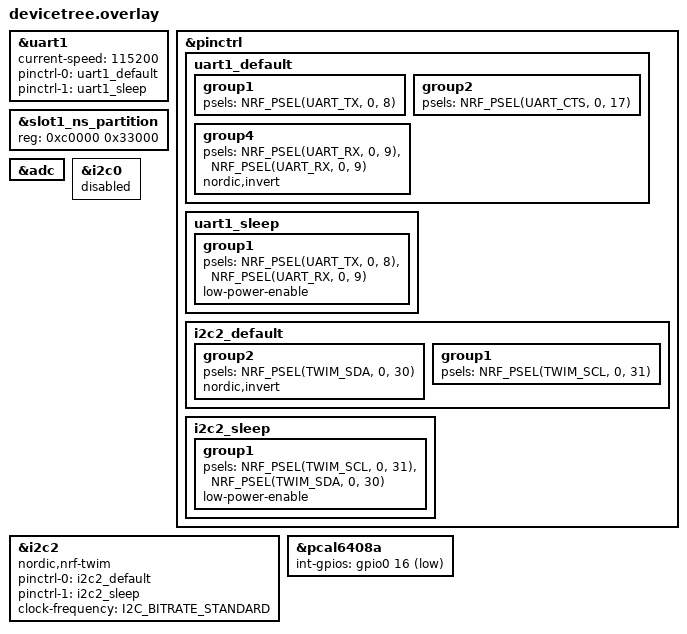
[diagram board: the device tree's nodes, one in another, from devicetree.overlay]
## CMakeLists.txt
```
cmake_minimum_required(VERSION 3.20.0)
find_package(Zephyr REQUIRED HINTS $ENV{ZEPHYR_BASE})
project(mbc_nrf9151_core_v1)

target_sources(app PRIVATE
  src/main.c
  src/biosignal.c
  src/ecg.c  
  src/i2c_helper.c
  src/spo2.c
  src/max30102.c
  src/robot.c
)
```

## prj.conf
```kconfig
# UART y consola
CONFIG_UART_INTERRUPT_DRIVEN=y
CONFIG_SERIAL=y
CONFIG_CONSOLE=y
CONFIG_UART_CONSOLE=y
CONFIG_STDOUT_CONSOLE=y

# GPIO y LED
CONFIG_GPIO=y

# Hilos y pila principal
CONFIG_MAIN_STACK_SIZE=1024
CONFIG_THREAD_NAME=y

# Logs y consola
CONFIG_PRINTK=y

# Librería C
CONFIG_NEWLIB_LIBC=y
CONFIG_NEWLIB_LIBC_FLOAT_PRINTF=y

# ADC
CONFIG_ADC=y
CONFIG_NRFX_SAADC=y

# Pin control
CONFIG_PINCTRL=y

# I2C
CONFIG_I2C=y
CONFIG_I2C_NRFX=y

CONFIG_HEAP_MEM_POOL_SIZE=8192
```

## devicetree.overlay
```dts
&uart1 {
    status = "okay";
    current-speed = <115200>;
    pinctrl-0 = <&uart1_default>;
    pinctrl-1 = <&uart1_sleep>;
    pinctrl-names = "default", "sleep";
};

&pinctrl {
    uart1_default: uart1_default {
        group1 {
            psels = <NRF_PSEL(UART_TX, 0, 8)>;
        };

        group2 {
            psels = <NRF_PSEL(UART_CTS, 0, 17)>;
        };

        group4 {
            psels = <NRF_PSEL(UART_RX, 0, 9)>, <NRF_PSEL(UART_RX, 0, 9)>;
            nordic,invert;
        };
    };

    uart1_sleep: uart1_sleep {
        group1 {
            psels = <NRF_PSEL(UART_TX, 0, 8)>,
                    <NRF_PSEL(UART_RX, 0, 9)>;
            low-power-enable;
        };
    };

};


&slot1_ns_partition {
    reg = <0xc0000 0x33000>;
};

&adc {
    status = "okay";
};

&i2c0 {
    status = "disabled";
};


&i2c2 {
    status = "okay";
    compatible = "nordic,nrf-twim";
    pinctrl-0 = <&i2c2_default>;
    pinctrl-1 = <&i2c2_sleep>;
    pinctrl-names = "default", "sleep";
    clock-frequency = <I2C_BITRATE_STANDARD>; // 100kHz
};

&pinctrl {
    i2c2_default: i2c2_default {

        group2 {
            psels = <NRF_PSEL(TWIM_SDA, 0, 30)>;
            nordic,invert;
        };

        group1 {
            psels = <NRF_PSEL(TWIM_SCL, 0, 31)>;
        };
    };

    i2c2_sleep: i2c2_sleep {
        group1 {
            psels = <NRF_PSEL(TWIM_SCL, 0, 31)>, <NRF_PSEL(TWIM_SDA, 0, 30)>;
            low-power-enable;
        };
    };
};
&pcal6408a {
    status = "okay";
    int-gpios = <&gpio0 16 (GPIO_ACTIVE_LOW | GPIO_PULL_UP)>;
};
```

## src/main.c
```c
#include <zephyr/kernel.h>
#include <zephyr/device.h>
#include <zephyr/devicetree.h>
#include <zephyr/drivers/uart.h>
#include <zephyr/sys/printk.h>
#include <stdio.h>
#include <string.h>

// My includes
#include "biosignal.h"
#include "ecg.h"
//#include "fcg.h"
#include "i2c_helper.h"
#include "robot.h"  
#include "max30102.h"

// UART
#define UART_NODE DT_NODELABEL(uart1)
const struct device *uart_dev;

// Semaphore to trigger each task
struct k_sem ecg_sem;
//struct k_sem fcg_sem;
struct k_sem max30102_sem;
struct k_sem i2c_sem;

// Thread stacks and structures
K_THREAD_STACK_DEFINE(ecg_stack, 1024);
//K_THREAD_STACK_DEFINE(fcg_stack, 1024);
K_THREAD_STACK_DEFINE(uart_stack, 1024);
K_THREAD_STACK_DEFINE(max30102_stack, 1024);
K_THREAD_STACK_DEFINE(i2c_stack, 1024);

struct k_thread ecg_thread_data;
//struct k_thread fcg_thread_data;
struct k_thread uart_thread_data;
struct k_thread i2c_thread_data;
struct k_thread max30102_thread_data;

k_tid_t ecg_tid;
//k_tid_t fcg_tid;
k_tid_t uart_tid;
k_tid_t i2c_tid;    
k_tid_t max30102_tid;    

robot_t robot;


void i2c_thread(void *arg1, void *arg2, void *arg3) {
    const struct device *i2c_dev = i2c_helper_init();

    if (i2c_dev == NULL) {
        printk("[I2C] Initialization failed.\n");
        return;
    }

    printk("Starting I2C bus scan...\n");

    for (uint8_t addr = 0x03; addr <= 0x77; addr++) {
        struct i2c_msg msg;
        uint8_t dummy_tx = 0x00;

        msg.buf = &dummy_tx;
        msg.len = 1;
        msg.flags = I2C_MSG_WRITE | I2C_MSG_STOP;

        int ret = i2c_transfer(i2c_dev, &msg, 1, addr);

        if (ret == 0) {
            printk("Found device at 0x%02X\n", addr);
        }
        k_msleep(10); // pequeña espera para no saturar el bus
    }

    printk("I2C scan complete.\n");


    while (1) {
        // Wait for the semaphore to be given
        // Uncomment the next line to block the thread until the semaphore is given
        //k_sem_take(&i2c_sem, K_FOREVER);


        //printk("[I2C] Thread.\n");

    }
}


// ecg data capture simulation
void ecg_thread(void *arg1, void *arg2, void *arg3) {
    printk("[ECG] ecg thread started and waiting for signal...\n");

    while (1) {
        k_sem_take(&ecg_sem, K_FOREVER);
        printk("[ECG] Capturing data...\n");

        float *captured_ecg = ecg_sample_task();
        if (captured_ecg == NULL) {
            printk("[ECG] Error capturing data.\n");
            continue;
        } else {
            //biosignal_send_data_generic("ecg", captured_ecg, ecg_SAMPLES, 10.5, 78);
            biosignal_send_data("ECG", captured_ecg, ECG_SAMPLES);

        }

        printk("[ECG] Capture complete. Returning to wait state.\n");
    }
}

// FCG data capture simulation
/*void fcg_thread(void *arg1, void *arg2, void *arg3) {
    printk("[FCG] FCG thread started and waiting for signal...\n");

    while (1) {
        k_sem_take(&fcg_sem, K_FOREVER);
        printk("[FCG] Capturing data...\n");

        float *captured_fcg = fcg_sample_task();
        if (captured_fcg == NULL) {
            printk("[FCG] Error capturing data.\n");
            continue;
        } else {
            //biosignal_send_data_generic("fcg", captured_fcg, fcg_SAMPLES, 10.5, 78);
            biosignal_send_data("FCG", captured_fcg, FCG_SAMPLES);

        }

        printk("[FCG] Capture complete. Returning to wait state.\n");
    }
}*/


void max30102_thread(void *arg1, void *arg2, void *arg3) {
    const struct device *i2c_dev = i2c_helper_init();

    if (i2c_dev == NULL) {
        printk("[MAX30102] Initialization failed.\n");
        return;
    }

    initMax30102(i2c_dev);
    printk("[MAX30102] PPG thread started and waiting for signal...\n");

    while (1) {
        k_sem_take(&max30102_sem, K_FOREVER);
        printk("[MAX30102] Capturing data...\n");

        float *red_data = get30sRedLed();
        if (red_data == NULL) {
            printk("[MAX30102] Error capturing data.\n");
            continue;
        } else {
    
            //biosignal_send_data_generic("PPG", red_data, MAX30102_BUFFER_SIZE, 10.5, 78);
            biosignal_send_data("PPG", red_data, MAX30102_BUFFER_SIZE);
        }

        printk("[MAX30102] Capture complete. Returning to wait state.\n");
    }
}

void uart_thread(void *arg1, void *arg2, void *arg3) {
    unsigned char ch;
    char cmd_buf[64];
    int cmd_index = 0;

    printk("[UART] UART thread started. Waiting for commands...\n");

    while (1) {
        if (uart_poll_in(uart_dev, &ch) == 0) {
            uart_poll_out(uart_dev, ch);  // echo

            if (ch == '\r' || ch == '\n') {
                cmd_buf[cmd_index] = '\0';
                printk("\n[UART] Command received: %s\n", cmd_buf);

                if (strstr(cmd_buf, "<CMD>:START:ECG;")) {
                    printk("[UART] Trigger ECG capture.\n");
                    k_sem_give(&ecg_sem);
                } else if (strstr(cmd_buf, "<CMD>:START:PPG;")) {
                    printk("[UART] Trigger PPG capture.\n");
                    k_sem_give(&max30102_sem);
                }else if (strstr(cmd_buf, "<CMD>:START:FCG;")) {
                    printk("[UART] Trigger FCG capture.\n");
                    k_sem_give(&ecg_sem);
                }

                cmd_index = 0;
                memset(cmd_buf, 0, sizeof(cmd_buf));
            } else {
                if (cmd_index < sizeof(cmd_buf) - 1) {
                    cmd_buf[cmd_index++] = ch;
                }
            }
        } else {
            k_msleep(1);
        }
    }
}

int main(void) {
    uart_dev = DEVICE_DT_GET(UART_NODE);
    if (!device_is_ready(uart_dev)) {
        printk("[ERROR] UART not ready\n");
        return -1;
    }

    printk("[SYSTEM] UART initialized\n");

    biosignal_init(uart_dev);
    ecg_adc_init();
    fcg_adc_init();

    k_sem_init(&ecg_sem, 0, 1);
    //k_sem_init(&fcg_sem, 0, 1);
    k_sem_init(&max30102_sem, 0, 1);

    ecg_tid = k_thread_create(&ecg_thread_data, ecg_stack,
                              K_THREAD_STACK_SIZEOF(ecg_stack),
                              ecg_thread,
                              NULL, NULL, NULL,
                              4, 0, K_NO_WAIT);
    k_thread_name_set(ecg_tid, "ECG Thread");

    /*fcg_tid = k_thread_create(&fcg_thread_data, fcg_stack,
                              K_THREAD_STACK_SIZEOF(fcg_stack),
                              fcg_thread,
                              NULL, NULL, NULL,
                              4, 0, K_NO_WAIT);
    k_thread_name_set(fcg_tid, "FCG Thread");*/

    uart_tid = k_thread_create(&uart_thread_data, uart_stack,
                               K_THREAD_STACK_SIZEOF(uart_stack),
                               uart_thread,
                               NULL, NULL, NULL,
                               5, 0, K_NO_WAIT);
    k_thread_name_set(uart_tid, "UART Thread");

    max30102_tid = k_thread_create(&max30102_thread_data, max30102_stack,
                                   K_THREAD_STACK_SIZEOF(max30102_stack),
                                   max30102_thread,
                                   NULL, NULL, NULL,
                                   3, 0, K_NO_WAIT);
    k_thread_name_set(max30102_tid, "PPG Thread");

    /*i2c_tid = k_thread_create(&i2c_thread_data, i2c_stack,
        K_THREAD_STACK_SIZEOF(i2c_stack),
        i2c_thread,
        NULL, NULL, NULL,
        3, 0, K_NO_WAIT);
    k_thread_name_set(i2c_tid, "I2C Thread");*/


    return 0;
}
```

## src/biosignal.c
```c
#include "biosignal.h"
#include <stdio.h>
#include <string.h>
#include <math.h>

float fake_ecg_data[ECG_LEN];
float temp = 36.7f;
int hr = 78;

static char rx_buffer[256];
static int rx_index = 0;

static const struct device *uart_dev = NULL;

char buf[1024];
int offset = 0;


void biosignal_handle_rx(char c) {
    if (c == '\n' || c == '\r') {
        rx_buffer[rx_index] = '\0';  // finalizar cadena

        if (strncmp(rx_buffer, "<CMD>:", 6) == 0) {
            char *cmd_ptr = strstr(rx_buffer, "ACTION=");
            if (cmd_ptr) {
                cmd_ptr += 7;  // avanzar a valor de acción
                char ack_buf[64];
                snprintf(ack_buf, sizeof(ack_buf), "<RESP>:ACK=%s;\n", cmd_ptr);
                biosignal_send_uart(ack_buf);
            }
        }

        rx_index = 0;  // reiniciar índice
    } else {
        if (rx_index < sizeof(rx_buffer) - 1) {
            rx_buffer[rx_index++] = c;
        } else {
            rx_index = 0;  // overflow: reinicia
        }
    }
}

void biosignal_init(const struct device *uart) {
    uart_dev = uart;
}


void biosignal_generate_fake_ecg(void) {
    for (int i = 0; i < ECG_LEN; i++) {
        fake_ecg_data[i] = 0.5f + 0.2f * sinf((float)i / 5.0f);  // señal simulada
    }
}

void biosignal_send_uart(const char *data) {
    for (size_t i = 0; i < strlen(data); i++) {
        uart_poll_out(uart_dev, data[i]);
    }
}

void biosignal_send_data(const char *signal_type, float *ecg_array, int len) {
    offset = 0;
    memset(buf, 0, sizeof(buf));  // Limpia el contenido previo del buffer

    printk("Sending %s data.\n", signal_type);
    offset += snprintf(buf + offset, sizeof(buf) - offset, "<DATA>:%s=[", signal_type);    

    for (int i = 0; i < len; i++) {
        offset += snprintf(buf + offset, sizeof(buf) - offset,
                           "%.4f%s", (double)ecg_array[i], (i < len - 1) ? "," : "");
        
        if (offset >= sizeof(buf) - 20) {  // Evita overflow
            break;
        }
    }

    offset += snprintf(buf + offset, sizeof(buf) - offset,
                       "];TEMP=%.1f;HR=%d;\n", (double)temp, hr);

    printk("Sending %s data.\n", signal_type);
    biosignal_send_uart(buf);

    k_msleep(10); 
    uart_poll_out(uart_dev, '\r');
    uart_poll_out(uart_dev, '\n');
    k_msleep(10);  // Permite que el hardware termine de enviar
}


void biosignal_send_data_generic(const char *signal_type, float *data_array, int len, float temp_val, int hr_val) {
    char buf[1024];
    int offset = 0;

    printk("Sending %s data.\n", signal_type);
    
    offset += snprintf(buf + offset, sizeof(buf) - offset, "<DATA>:%s=[", signal_type);

    for (int i = 0; i < len; i++) {
        offset += snprintf(buf + offset, sizeof(buf) - offset,
                           "%.4f%s", (double)data_array[i], (i < len - 1) ? "," : "");
        
        if (offset >= sizeof(buf) - 20) {  // Prevent overflow
            break;
        }
    }

    offset += snprintf(buf + offset, sizeof(buf) - offset,
                       "];TEMP=%.1f;HR=%d;\n", (double)temp_val, hr_val);

    printk("Sending %s data.\n", signal_type);
    biosignal_send_uart(buf);
}
```

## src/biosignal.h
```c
#ifndef BIOSIGNAL_H
#define BIOSIGNAL_H

#include <zephyr/device.h>
#include <zephyr/devicetree.h>
#include <zephyr/drivers/uart.h>
#include <zephyr/kernel.h>
// Después (correcto)
#include <stddef.h>  // para size_t

#define ECG_LEN 128

extern float ecg_data[ECG_LEN];
extern float temp;
extern int hr;

void biosignal_init(const struct device *uart);
void biosignal_generate_fake_ecg(void);
void biosignal_handle_rx(char c);
void biosignal_send_data(const char *signal_type, float *ecg_array, int len);
void biosignal_send_uart(const char *data);
void biosignal_send_data_generic(const char *signal_type, float *data_array, int len, float temp_val, int hr_val);

#endif // BIOSIGNAL_H
```

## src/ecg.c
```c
// ecg_adc.c
#include <nrfx_saadc.h>

#include "ecg.h"
#include <zephyr/kernel.h>
#include <zephyr/sys/printk.h>
#include <zephyr/drivers/adc.h>
#include <string.h>


const struct device *ecg_adc_dev = NULL;
uint16_t ecg_data[ECG_SAMPLES];
static struct adc_channel_cfg adc_cfg;
static struct adc_sequence sequence;
static uint16_t sample_buffer[ECG_SAMPLES];

int ecg_adc_init(void) {
    ecg_adc_dev = DEVICE_DT_GET(DT_NODELABEL(adc));
    if (!device_is_ready(ecg_adc_dev)) {
        printk("ADC device not ready\n");
        return -1;
    }

    adc_cfg.channel_id = ECG_ADC_CHANNEL;
    adc_cfg.gain = ECG_ADC_GAIN;
    adc_cfg.reference = ECG_ADC_REFERENCE;
    adc_cfg.acquisition_time = ECG_ADC_ACQUISITION_TIME;
    adc_cfg.input_positive = ECG_ADC_INPUT;

    int ret = adc_channel_setup(ecg_adc_dev, &adc_cfg);
    if (ret != 0) {
        printk("ADC channel setup failed (%d)\n", ret);
        return ret;
    }

    sequence.options = NULL;
    sequence.channels = BIT(ECG_ADC_CHANNEL);
    sequence.buffer = sample_buffer;
    sequence.buffer_size = sizeof(sample_buffer);
    sequence.resolution = ECG_ADC_RESOLUTION;

    return 0;
}


int fcg_adc_init(void) {
    ecg_adc_dev = DEVICE_DT_GET(DT_NODELABEL(adc));
    if (!device_is_ready(ecg_adc_dev)) {
        printk("ADC device not ready\n");
        return -1;
    }

    adc_cfg.channel_id = FCG_ADC_CHANNEL;
    adc_cfg.gain = ECG_ADC_GAIN;
    adc_cfg.reference = ECG_ADC_REFERENCE;
    adc_cfg.acquisition_time = ECG_ADC_ACQUISITION_TIME;
    adc_cfg.input_positive = FCG_ADC_INPUT;

    int ret = adc_channel_setup(ecg_adc_dev, &adc_cfg);
    if (ret != 0) {
        printk("ADC channel setup failed (%d)\n", ret);
        return ret;
    }

    sequence.options = NULL;
    sequence.channels = BIT(ECG_ADC_CHANNEL);
    sequence.buffer = sample_buffer;
    sequence.buffer_size = sizeof(sample_buffer);
    sequence.resolution = ECG_ADC_RESOLUTION;

    return 0;
}


/*void ecg_sample_task(void) {
    for (int i = 0; i < ECG_SAMPLES; i++) {
        int ret = adc_read(adc_dev, &sequence);
        if (ret != 0) {
            printk("ADC read failed: %d\n", ret);
            break;
        }
        ecg_data[i] = sample_buffer[0];
        k_sleep(K_MSEC(1));  // 1kHz sampling
    }
    printk("ECG sampling complete\n");
}*/

float* ecg_sample_task(void) {
    static float ecg_data[ECG_SAMPLES];

    for (int i = 0; i < ECG_SAMPLES; i++) {
        int ret = adc_read(ecg_adc_dev, &sequence);
        if (ret != 0) {
            printk("ADC read failed: %d\n", ret);
            return NULL;
        }
        // Convert ADC sample to millivolts
        float millivolts = ((float)sample_buffer[0]) * (SAADC_REF_VOLTAGE / SAADC_GAIN) * 1000.0f / ADC_RESOLUTION;
        //printk("Sample %d: %d mV\n", i, (float)millivolts);
        ecg_data[i] = millivolts;
        k_sleep(K_MSEC(1));  // 1kHz sampling rate
    }

    printk("ECG sampling complete\n");
    return ecg_data;
}

float* fcg_sample_task(void) {
    static float ecg_data[ECG_SAMPLES];

    for (int i = 0; i < ECG_SAMPLES; i++) {
        int ret = adc_read(ecg_adc_dev, &sequence);
        if (ret != 0) {
            printk("ADC read failed: %d\n", ret);
            return NULL;
        }
        // Convert ADC sample to millivolts
        float millivolts = ((float)sample_buffer[0]) * (SAADC_REF_VOLTAGE / SAADC_GAIN) * 1000.0f / ADC_RESOLUTION;
        //printk("Sample %d: %d mV\n", i, (float)millivolts);
        ecg_data[i] = millivolts;
        k_sleep(K_MSEC(1));  // 1kHz sampling rate
    }

    printk("FCG sampling complete\n");
    return ecg_data;
}
```

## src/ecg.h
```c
#ifndef ECG_ADC_H
#define ECG_ADC_H

#include <zephyr/device.h>
#include <zephyr/drivers/adc.h>
#include <zephyr/kernel.h>

#define ECG_SAMPLES         30000      // 30 segundos a 1kHz
#define ECG_ADC_RESOLUTION  12         // 12 bits
#define ECG_ADC_CHANNEL     0          // Canal AIN0
#define ECG_ADC_INPUT       NRF_SAADC_INPUT_AIN0
#define ECG_ADC_GAIN        ADC_GAIN_1_6
#define ECG_ADC_REFERENCE   ADC_REF_INTERNAL
#define ECG_ADC_ACQUISITION_TIME ADC_ACQ_TIME(ADC_ACQ_TIME_MICROSECONDS, 10)
#define ECG_ADC_NODE        DT_LABEL(DT_NODELABEL(adc))

#define FCG_ADC_CHANNEL     1          // Canal AIN1
#define FCG_ADC_INPUT       NRF_SAADC_INPUT_AIN1

#define SAADC_GAIN         (1.0f / 6.0f)
#define SAADC_REF_VOLTAGE  0.6f  // V
#define ADC_RESOLUTION     4096.0f  // 12 bits


extern int16_t ecg_buffer[ECG_SAMPLES];  // Buffer para los datos crudos
extern struct k_sem ecg_done;            // Semáforo para indicar fin de adquisición

int ecg_adc_init(void);
int fcg_adc_init(void);
//void ecg_sample_task(void);
float* ecg_sample_task(void);
float* fcg_sample_task(void);

    
#endif // ECG_ADC_H
```

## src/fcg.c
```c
// fcg_adc.c
#include <nrfx_saadc.h>

#include "fcg.h"
#include <zephyr/kernel.h>
#include <zephyr/sys/printk.h>
#include <zephyr/drivers/adc.h>
#include <string.h>


const struct device *fcg_adc_dev = NULL;
uint16_t fcg_data[FCG_SAMPLES];
static struct adc_channel_cfg adc_cfg;
static struct adc_sequence sequence;
static uint16_t sample_buffer[FCG_SAMPLES];

int fcg_adc_init(void) {
    fcg_adc_dev = DEVICE_DT_GET(DT_NODELABEL(adc));
    if (!device_is_ready(fcg_adc_dev)) {
        printk("ADC device not ready\n");
        return -1;
    }

    adc_cfg.channel_id = FCG_ADC_CHANNEL;
    adc_cfg.gain = FCG_ADC_GAIN;
    adc_cfg.reference = FCG_ADC_REFERENCE;
    adc_cfg.acquisition_time = FCG_ADC_ACQUISITION_TIME;
    adc_cfg.input_positive = FCG_ADC_INPUT;

    int ret = adc_channel_setup(fcg_adc_dev, &adc_cfg);
    if (ret != 0) {
        printk("ADC channel setup failed (%d)\n", ret);
        return ret;
    }

    sequence.options = NULL;
    sequence.channels = BIT(FCG_ADC_CHANNEL);
    sequence.buffer = sample_buffer;
    sequence.buffer_size = sizeof(sample_buffer);
    sequence.resolution = FCG_ADC_RESOLUTION;

    return 0;
}

/*void fcg_sample_task(void) {
    for (int i = 0; i < FCG_SAMPLES; i++) {
        int ret = adc_read(adc_dev, &sequence);
        if (ret != 0) {
            printk("ADC read failed: %d\n", ret);
            break;
        }
        fcg_data[i] = sample_buffer[0];
        k_sleep(K_MSEC(1));  // 1kHz sampling
    }
    printk("FCG sampling complete\n");
}*/

float* fcg_sample_task(void) {
    static float fcg_data[FCG_SAMPLES];

    for (int i = 0; i < FCG_SAMPLES; i++) {
        int ret = adc_read(fcg_adc_dev, &sequence);
        if (ret != 0) {
            printk("ADC read failed: %d\n", ret);
            return NULL;
        }
        // Convert ADC sample to millivolts
        float millivolts = ((float)sample_buffer[0]) * (SAADC_REF_VOLTAGE / SAADC_GAIN) * 1000.0f / ADC_RESOLUTION;
        //printk("Sample %d: %d mV\n", i, (float)millivolts);
        fcg_data[i] = millivolts;
        k_sleep(K_MSEC(1));  // 1kHz sampling rate
    }

    printk("FCG sampling complete\n");
    return fcg_data;
}
```

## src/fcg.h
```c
#ifndef FCG_ADC_H
#define FCG_ADC_H

#include <zephyr/device.h>
#include <zephyr/drivers/adc.h>
#include <zephyr/kernel.h>

#define FCG_SAMPLES         30000      // 30 segundos a 1kHz
#define FCG_ADC_RESOLUTION  12         // 12 bits
#define FCG_ADC_CHANNEL     0          // Canal AIN0
#define FCG_ADC_INPUT       NRF_SAADC_INPUT_AIN1
#define FCG_ADC_GAIN        ADC_GAIN_1_6
#define FCG_ADC_REFERENCE   ADC_REF_INTERNAL
#define FCG_ADC_ACQUISITION_TIME ADC_ACQ_TIME(ADC_ACQ_TIME_MICROSECONDS, 10)
#define FCG_ADC_NODE        DT_LABEL(DT_NODELABEL(adc))

#define SAADC_GAIN         (1.0f / 6.0f)
#define SAADC_REF_VOLTAGE  0.6f  // V
#define ADC_RESOLUTION     4096.0f  // 12 bits


extern int16_t fcg_buffer[FCG_SAMPLES];  // Buffer para los datos crudos
extern struct k_sem fcg_done;            // Semáforo para indicar fin de adquisición

int fcg_adc_init(void);
//void fcg_sample_task(void);
float* fcg_sample_task(void);

    
#endif // FCG_ADC_H
```

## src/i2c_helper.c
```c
#include "i2c_helper.h"
#include <zephyr/kernel.h>
#include <zephyr/sys/printk.h>
#include <math.h>
#include "max30102.h"
#include "spo2.h"



#define LED_BRIGHTNESS   0x1F
#define SAMPLE_AVG       2  // SAMPLEAVG_4
#define LED_MODE         3  // MODE_RED_IR
#define SAMPLE_RATE      3  // SAMPLERATE_400
#define PULSE_WIDTH      3  // PULSEWIDTH_411
#define ADC_RANGE        1  // ADCRANGE_4096
 
max30102_t sensor;

const struct device *i2c_helper_init(void) {
    const struct device *i2c_dev = DEVICE_DT_GET(I2C_HELPER_NODE);
    
    if (!device_is_ready(i2c_dev)) {
        printk("I2C: Device not ready.\n");
        return NULL;
    }

    return i2c_dev;
}

int i2c_helper_read_reg(const struct device *i2c_dev, uint8_t dev_addr, uint8_t reg_addr, uint8_t *value) {
    //return i2c_write_read(i2c_dev, dev_addr, &reg_addr, sizeof(reg_addr), value, sizeof(*value));
    uint8_t NORMAL_OPERATION_MODE[] = {reg_addr, 0, 0};
    return i2c_write(i2c_dev, NORMAL_OPERATION_MODE, 3, dev_addr);

}

void initMax30102(const struct device *i2c_dev) {
    // Initialize MAX30102 Settings
    
    if (max30102_begin(&sensor, i2c_dev, MAX30102_IIC_ADDRESS) != 0) {
        printk("MAX30102 not found\n");
        return;
    }

    printk("MAX30102 found and initialized\n");

    max30102_sensor_configure(&sensor, LED_BRIGHTNESS, SAMPLE_AVG, LED_MODE, SAMPLE_RATE, PULSE_WIDTH, ADC_RANGE);

}

void getHearthRate(){
    
    int32_t spo2, heart_rate;
    int8_t spo2_valid, hr_valid;
    max30102_read_fifo_and_calculate(&sensor, &spo2, &spo2_valid, &heart_rate, &hr_valid);

    printk("Heart Rate: %d bpm [%s], SpO2: %d %% [%s]\n",
           heart_rate,
           hr_valid ? "valid" : "invalid",
           spo2,
           spo2_valid ? "valid" : "invalid");

    k_sleep(K_SECONDS(5));  // Espera entre lecturas
}

void readRedLedPPG(){
    uint32_t red_values =  max30102_get_red(&sensor);
    printk("%d\n", red_values);
    k_sleep(K_MSEC(100));
}

void readIRLedPPG(){
    uint32_t red_values =  max30102_get_ir(&sensor);
    printk("%d\n", red_values);
    k_sleep(K_MSEC(100));
}

float* get30sRedLed(){
    printk("Capturing 30s of Red LED data...\n");
    float* red_data = capture_red_led_data(&sensor);
    //printk("Captured Red LED data: %u\n", red_data[0]);

    return red_data;
}


void configI2C(const struct device *i2c_dev) {
    printk("Configuring I2C...\n");
}
```

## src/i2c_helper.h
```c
#ifndef I2C_HELPER_H
#define I2C_HELPER_H

#include <zephyr/device.h>
#include <zephyr/drivers/i2c.h>
#include <stdint.h>




// Node label for the I2C device
#define I2C_HELPER_NODE DT_NODELABEL(i2c2)

// Initialize the I2C device
const struct device *i2c_helper_init(void);

// Read a single register from the I2C slave
int i2c_helper_read_reg(const struct device *i2c_dev, uint8_t dev_addr, uint8_t reg_addr, uint8_t *value);


void initMax30102(const struct device *i2c_dev);
void getHearthRate(void);
void configI2C(const struct device *i2c_dev);
void readRedLedPPG();
void readIRLedPPG();
float* get30sRedLed();


#endif  // I2C_HELPER_H
```

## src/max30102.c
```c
#include <stdio.h>
#include <stdint.h>
#include <stdbool.h>  
#include <zephyr/device.h>
#include <zephyr/drivers/i2c.h>
#include <zephyr/sys/printk.h>
#include "spo2.h"
#include "max30102.h"

int max30102_write_reg(max30102_t *dev, uint8_t reg, const void *buf, uint8_t len)
{
    uint8_t tx_buf[len + 1];
    tx_buf[0] = reg;
    memcpy(&tx_buf[1], buf, len);
    return i2c_write(dev->i2c_dev, tx_buf, len + 1, dev->i2c_addr);
}

int max30102_read_reg(max30102_t *dev, uint8_t reg, void *buf, uint8_t len)
{
    int ret = i2c_write_read(dev->i2c_dev, dev->i2c_addr, &reg, 1, buf, len);
    return ret;
}

int max30102_begin(max30102_t *dev, const struct device *i2c_dev, uint8_t addr)
{
    dev->i2c_dev = i2c_dev;
    dev->i2c_addr = addr;
    dev->active_leds = 2;
    memset(&dev->buffer, 0, sizeof(dev->buffer));

    uint8_t part_id;
    if (max30102_get_part_id(dev) != MAX30102_EXPECTED_PARTID) {
        printk("MAX30102: Invalid part ID\n");
        return -1;
    }

    max30102_soft_reset(dev);
    return 0;
}

void max30102_soft_reset(max30102_t *dev)
{
    uint8_t mode_cfg;
    max30102_read_reg(dev, MAX30102_MODECONFIG, &mode_cfg, 1);
    mode_cfg |= 0x40;  // Set RESET bit
    max30102_write_reg(dev, MAX30102_MODECONFIG, &mode_cfg, 1);

    // Esperar a que se borre el bit RESET
    uint32_t start_time = k_uptime_get();
    while (k_uptime_get() - start_time < 100) {
        max30102_read_reg(dev, MAX30102_MODECONFIG, &mode_cfg, 1);
        if ((mode_cfg & 0x40) == 0) break;
        k_msleep(1);
    }
}

uint8_t max30102_get_part_id(max30102_t *dev)
{
    uint8_t part_id = 0;
    max30102_read_reg(dev, MAX30102_PARTID, &part_id, 1);
    return part_id;
}

float max30102_read_temp_c(max30102_t *dev)
{
    uint8_t config = 0x01;
    max30102_write_reg(dev, MAX30102_DIETEMPCONFIG, &config, 1);

    uint32_t start = k_uptime_get();
    while (k_uptime_get() - start < 100) {
        max30102_read_reg(dev, MAX30102_DIETEMPCONFIG, &config, 1);
        if ((config & 0x01) == 0) break;
        k_msleep(1);
    }

    uint8_t temp_int, temp_frac;
    max30102_read_reg(dev, MAX30102_DIETEMPINT, &temp_int, 1);
    max30102_read_reg(dev, MAX30102_DIETEMPFRAC, &temp_frac, 1);

    return temp_int + (temp_frac * 0.0625f);
}

float max30102_read_temp_f(max30102_t *dev)
{
    return max30102_read_temp_c(dev) * 1.8f + 32.0f;
}

static uint8_t max30102_get_write_pointer(max30102_t *dev)
{
    uint8_t wp = 0;
    max30102_read_reg(dev, MAX30102_FIFOWRITEPTR, &wp, 1);
    return wp;
}

static uint8_t max30102_get_read_pointer(max30102_t *dev)
{
    uint8_t rp = 0;
    max30102_read_reg(dev, MAX30102_FIFOREADPTR, &rp, 1);
    return rp;
}

void max30102_get_new_data(max30102_t *dev)
{
    uint8_t read_ptr = max30102_get_read_pointer(dev);
    uint8_t write_ptr = max30102_get_write_pointer(dev);
    int32_t num_samples = write_ptr - read_ptr;

    if (num_samples < 0)
        num_samples += 32;

    int32_t bytes_to_read = num_samples * dev->active_leds * 3;

    while (bytes_to_read > 0) {
        uint8_t fifo_data[6] = {0};
        max30102_read_reg(dev, MAX30102_FIFODATA, fifo_data, dev->active_leds * 3);

        uint32_t ir = 0, red = 0;
        if (dev->active_leds > 1) {
            ir = ((fifo_data[0] << 16) | (fifo_data[1] << 8) | fifo_data[2]) & 0x3FFFF;
            red = ((fifo_data[3] << 16) | (fifo_data[4] << 8) | fifo_data[5]) & 0x3FFFF;
        } else {
            red = ((fifo_data[0] << 16) | (fifo_data[1] << 8) | fifo_data[2]) & 0x3FFFF;
        }

        dev->buffer.head = (dev->buffer.head + 1) % MAX30102_BUF_SIZE;
        dev->buffer.red[dev->buffer.head] = red;
        dev->buffer.ir[dev->buffer.head] = ir;

        bytes_to_read -= dev->active_leds * 3;
    }
}

uint32_t max30102_get_red(max30102_t *dev)
{
    max30102_get_new_data(dev);
    return dev->buffer.red[dev->buffer.head];
}

uint32_t max30102_get_ir(max30102_t *dev)
{
    max30102_get_new_data(dev);
    return dev->buffer.ir[dev->buffer.head];
}


static void max30102_set_fifo_average(max30102_t *dev, uint8_t samples)
{
    uint8_t fifo;
    max30102_read_reg(dev, MAX30102_FIFOCONFIG, &fifo, 1);
    fifo = (fifo & 0x8F) | ((samples & 0x07) << 4);
    max30102_write_reg(dev, MAX30102_FIFOCONFIG, &fifo, 1);
}

static void max30102_set_adc_range(max30102_t *dev, uint8_t range)
{
    uint8_t cfg;
    max30102_read_reg(dev, MAX30102_PARTICLECONFIG, &cfg, 1);
    cfg = (cfg & 0x9F) | ((range & 0x03) << 5);
    max30102_write_reg(dev, MAX30102_PARTICLECONFIG, &cfg, 1);
}

static void max30102_set_sample_rate(max30102_t *dev, uint8_t rate)
{
    uint8_t cfg;
    max30102_read_reg(dev, MAX30102_PARTICLECONFIG, &cfg, 1);
    cfg = (cfg & 0xE3) | ((rate & 0x07) << 2);
    max30102_write_reg(dev, MAX30102_PARTICLECONFIG, &cfg, 1);
}

static void max30102_set_pulse_width(max30102_t *dev, uint8_t width)
{
    uint8_t cfg;
    max30102_read_reg(dev, MAX30102_PARTICLECONFIG, &cfg, 1);
    cfg = (cfg & 0xFC) | (width & 0x03);
    max30102_write_reg(dev, MAX30102_PARTICLECONFIG, &cfg, 1);
}

static void max30102_set_led_mode(max30102_t *dev, uint8_t mode)
{
    uint8_t cfg;
    max30102_read_reg(dev, MAX30102_MODECONFIG, &cfg, 1);
    cfg = (cfg & 0xF8) | (mode & 0x07);
    max30102_write_reg(dev, MAX30102_MODECONFIG, &cfg, 1);
}

static void max30102_set_led_amplitude(max30102_t *dev, uint8_t red, uint8_t ir)
{
    max30102_write_reg(dev, MAX30102_LED1_PULSEAMP, &red, 1);
    max30102_write_reg(dev, MAX30102_LED2_PULSEAMP, &ir, 1);
}

static void max30102_enable_slot1(max30102_t *dev, uint8_t value)
{
    uint8_t reg;
    max30102_read_reg(dev, MAX30102_MULTILEDCONFIG1, &reg, 1);
    reg = (reg & 0xF0) | (value & 0x0F);
    max30102_write_reg(dev, MAX30102_MULTILEDCONFIG1, &reg, 1);
}

static void max30102_enable_slot2(max30102_t *dev, uint8_t value)
{
    uint8_t reg;
    max30102_read_reg(dev, MAX30102_MULTILEDCONFIG1, &reg, 1);
    reg = (reg & 0x0F) | ((value & 0x0F) << 4);
    max30102_write_reg(dev, MAX30102_MULTILEDCONFIG1, &reg, 1);
}

static void max30102_enable_fifo_rollover(max30102_t *dev)
{
    uint8_t fifo;
    max30102_read_reg(dev, MAX30102_FIFOCONFIG, &fifo, 1);
    fifo |= 0x10; // bit 4 = FIFO_ROLLOVER_EN
    max30102_write_reg(dev, MAX30102_FIFOCONFIG, &fifo, 1);
}

static void max30102_reset_fifo(max30102_t *dev)
{
    uint8_t zero = 0;
    max30102_write_reg(dev, MAX30102_FIFOWRITEPTR, &zero, 1);
    max30102_write_reg(dev, MAX30102_FIFOOVERFLOW, &zero, 1);
    max30102_write_reg(dev, MAX30102_FIFOREADPTR, &zero, 1);
}

void max30102_sensor_configure(max30102_t *dev,
    uint8_t led_brightness,
    uint8_t sample_avg,
    uint8_t led_mode,
    uint8_t sample_rate,
    uint8_t pulse_width,
    uint8_t adc_range)
{
    max30102_set_fifo_average(dev, sample_avg);
    max30102_set_adc_range(dev, adc_range);
    max30102_set_sample_rate(dev, sample_rate);
    max30102_set_pulse_width(dev, pulse_width);
    max30102_set_led_amplitude(dev, led_brightness, led_brightness);

    max30102_enable_slot1(dev, 1); // RED
    if (led_mode > 2)
        max30102_enable_slot2(dev, 2); // IR

    max30102_set_led_mode(dev, led_mode);
    dev->active_leds = (led_mode == 2) ? 1 : 2;

    max30102_enable_fifo_rollover(dev);
    max30102_reset_fifo(dev);
}

void max30102_read_fifo_and_calculate(
    max30102_t *dev,
    int32_t *spo2,
    int8_t *spo2_valid,
    int32_t *hr,
    int8_t *hr_valid)
{
    uint32_t ir_buffer_fifo[100];
    uint32_t red_buffer_fifo[100];
    int32_t collected = 0;

    while (collected < 100) {
        max30102_get_new_data(dev);  // llena buffer interno

        int8_t samples = dev->buffer.head - dev->buffer.tail;
        if (samples < 0) samples += MAX30102_BUF_SIZE;

        while (samples-- && collected < 100) {
            red_buffer_fifo[collected] = dev->buffer.red[dev->buffer.tail];
            ir_buffer_fifo[collected] = dev->buffer.ir[dev->buffer.tail];
            dev->buffer.tail = (dev->buffer.tail + 1) % MAX30102_BUF_SIZE;
            collected++;
        }

        k_msleep(5);  // breve espera para nuevas muestras
    }

    maxim_heart_rate_and_oxygen_saturation(
        ir_buffer_fifo,
        100,
        red_buffer_fifo,
        spo2,
        spo2_valid,
        hr,
        hr_valid
    );
}


float* capture_red_led_data(max30102_t *dev)
{
    uint32_t start_time = k_uptime_get(); 
    uint32_t elapsed = 0;
    int index = 0;

    memset(red_buffer, 0, sizeof(red_buffer)); // Asegura datos limpios

    while (elapsed < MAX30102_CAPTURE_DURATION_SEC * 1000 && index < MAX30102_BUFFER_SIZE) {
        uint32_t red_val = max30102_get_red(dev); 
        red_buffer[index++] = (float)red_val;

        printk("[MAX30102] Sample %d: %u (elapsed: %ums)\n", index, red_val, elapsed);

        k_msleep(1000 / MAX30102_SAMPLING_FREQ_HZ);  
        elapsed = k_uptime_get() - start_time;
    }

    printk("[MAX30102] Finished capture. Total samples: %d\n", index);
    return red_buffer;
}
```

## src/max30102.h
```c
#ifndef MAX30102_H
#define MAX30102_H

#include <zephyr/types.h>
#include <stdio.h>
#include <stdint.h>
#include <stdbool.h>  
#include <zephyr/device.h>
#include <zephyr/drivers/i2c.h>
#include <zephyr/sys/printk.h>

#define MAX30102_IIC_ADDRESS  0x57 //I2C Address

//Status Registers
#define MAX30102_INTSTAT1        0x00//Interrupt Status1
#define MAX30102_INTSTAT2        0x01//Interrupt Status2
#define MAX30102_INTENABLE1      0x02//Interrupt Enable1
#define MAX30102_INTENABLE2      0x03//Interrupt Enable2
//FIFO Registers
#define MAX30102_FIFOWRITEPTR    0x04//FIFO Write Pointer, The FIFO Write Pointer points to the location where the MAX30102 writes the next sample. This pointer advances for each sample pushed on to the FIFO. It can also be changed through the I2C interface when MODE[2:0] is 010, 011, or 111.
#define MAX30102_FIFOOVERFLOW    0x05//FIFO Overflow Counter, When the FIFO is full, samples are not pushed on to the FIFO, samples are lost. OVF_COUNTER counts the number of samples lost. It saturates at 0x1F. When a complete sample is “popped” (i.e., removal of old FIFO data and shifting the samples down) from the FIFO (when the read pointer advances), OVF_COUNTER is reset to zero.
#define MAX30102_FIFOREADPTR     0x06//FIFO Read Pointer, The FIFO Read Pointer points to the location from where the processor gets the next sample from the FIFO through the I2C interface. This advances each time a sample is popped from the FIFO. The processor can also write to this pointer after reading the samples to allow rereading samples from the FIFO if there is a data communication error.
#define MAX30102_FIFODATA        0x07//FIFO Data Register, The circular FIFO depth is 32 and can hold up to 32 samples of data. The sample size depends on the number of LED channels (a.k.a. channels) configured as active. As each channel signal is stored as a 3-byte data signal, the FIFO width can be 3 bytes or 6 bytes in size.
//Configuration Registers
#define MAX30102_FIFOCONFIG      0x08//FIFO Configuration
#define MAX30102_MODECONFIG      0x09//Mode Configuration
#define MAX30102_PARTICLECONFIG  0x0A//SpO2 Configuration
#define MAX30102_LED1_PULSEAMP   0x0C//LED1 Pulse Amplitude
#define MAX30102_LED2_PULSEAMP   0x0D//LED2 Pulse Amplitude
#define MAX30102_LED3_PULSEAMP   0x0E//RESERVED
#define MAX30102_LED_PROX_AMP    0x10//RESERVED
#define MAX30102_MULTILEDCONFIG1 0x11//Multi-LED Mode Control Registers
#define MAX30102_MULTILEDCONFIG2 0x12//Multi-LED Mode Control Registers
//Die Temperature Registers
#define MAX30102_DIETEMPINT      0x1F//Die Temp Integer
#define MAX30102_DIETEMPFRAC     0x20//Die Temp Fraction
#define MAX30102_DIETEMPCONFIG   0x21//Die Temperature Config
#define MAX30102_PROXINTTHRESH   0x30//RESERVED
//Part ID Registers
#define MAX30102_REVISIONID      0xFE//Revision ID
#define MAX30102_PARTID          0xFF//Part ID:0x15
#define MAX30102_EXPECTED_PARTID  0x15

#define MAX30102_REG_FIFO_DATA  0x07
#define MAX30102_BUF_SIZE 32

#define MAX30102_CAPTURE_DURATION_SEC 30
#define MAX30102_SAMPLING_FREQ_HZ     25  // Ajusta según tu configuración
#define MAX30102_BUFFER_SIZE          (MAX30102_CAPTURE_DURATION_SEC * MAX30102_SAMPLING_FREQ_HZ)

static float red_buffer[MAX30102_BUFFER_SIZE];


typedef struct {
    uint32_t red[MAX30102_BUF_SIZE];
    uint32_t ir[MAX30102_BUF_SIZE];
    uint8_t head;
    uint8_t tail;
} max30102_buffer_t;

typedef struct {
    const struct device *i2c_dev;
    uint8_t i2c_addr;
    max30102_buffer_t buffer;
    uint8_t active_leds;
} max30102_t;

/*typedef struct {
    uint32_t red[MAX30102_BUF_SIZE];
    uint32_t ir[MAX30102_BUF_SIZE];
    uint8_t head;
    uint8_t tail;
    uint8_t active_leds;
    const struct device *i2c_dev;
    uint16_t i2c_addr;
} max30102_t;*/

typedef struct {
    uint8_t led_brightness;
    uint8_t sample_avg;
    uint8_t led_mode;
    uint8_t sample_rate;
    uint8_t pulse_width;
    uint8_t adc_range;
} max30102_config_t;

// API pública
int max30102_begin(max30102_t *dev, const struct device *i2c_dev, uint8_t addr);
int max30102_configure(max30102_t *dev, const max30102_config_t *cfg);
int max30102_read_fifo(max30102_t *dev, uint32_t *red, uint32_t *ir);
int max30102_read_temperature(max30102_t *dev, float *temp_c);
uint8_t max30102_get_part_id(max30102_t *dev);

void max30102_soft_reset(max30102_t *dev);
void max30102_sensor_configure(max30102_t *dev,
    uint8_t led_brightness,
    uint8_t sample_avg,
    uint8_t led_mode,
    uint8_t sample_rate,
    uint8_t pulse_width,
    uint8_t adc_range);

void max30102_read_fifo_and_calculate(
        max30102_t *dev,
        int32_t *spo2,
        int8_t *spo2_valid,
        int32_t *hr,
        int8_t *hr_valid);

void max30102_get_new_data(max30102_t *dev);
uint32_t max30102_get_red(max30102_t *dev);
uint32_t max30102_get_ir(max30102_t *dev);
void readIRLedPPG();
void readRedLedPPG();
float* capture_red_led_data(max30102_t *dev);


#endif // MAX30102_H
```

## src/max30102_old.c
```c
// https://www.hackster.io/taifur/wearable-pulse-oximeter-a1361e

#include <stdio.h>
#include <stdint.h>
#include <stdbool.h>  
#include "max30102.h"
#include <zephyr/device.h>
#include <zephyr/drivers/i2c.h>
#include <zephyr/sys/printk.h>

int MAX30102_check(const struct device *dev_i2c)
{
    uint8_t partid[1] = {0x0};
    int ret = i2c_burst_read(dev_i2c, MAX30102_ADDRESS, MAX30102_PARTID, partid, 1);    // Read part ID 
	
    if(ret) printk("MAX30102 not present!\n");
    else
      {
      if (partid[0] == 0x15) printk("MAX30102: present! Part ID: %dd\n", partid[0]);
      else
        { 
        printk("MAX30102: Error! Part ID: %dd\n", partid[0]);
        ret = 0;
        }
      }
    return ret;
}

int MAX30102_reset(const struct device *dev_i2c)     // This function resets the MAX30102
{
    uint8_t sendbuf[1] = {MAX30102_RESET};
    int ret = i2c_reg_write_byte(dev_i2c, MAX30102_ADDRESS, MAX30102_MODE_CONFIG, sendbuf[0]);
	
    if(ret) printk("Reset Error!\n");
    else printk("Reset done!\n");
    return ret;
}

int MAX30102_clear(const struct device *dev_i2c)     // Reads/clears the interrupt status register
{
    uint8_t IntStatus1[1] = {0x0};
    int ret = i2c_burst_read(dev_i2c, MAX30102_ADDRESS, MAX30102_INT_STATUS_1, IntStatus1, 1);
    
    if(ret) printk("MAX30102: Interrupt Status 1: Error!\n");
    else printk("MAX30102: Interrupt Status 1: Ok (%d)\n", IntStatus1[0]);
    return ret;
}

int MAX30102_config(const struct device *dev_i2c)     
{
    uint8_t buf[1] = {0x00};
    int ret, ret1 = 0;

    buf[0] = 0xC0;
    ret =  i2c_reg_write_byte(dev_i2c, MAX30102_ADDRESS, MAX30102_INT_ENABLE_1, buf[0]);
    if(ret)
      {
      ret1 = 0;
      }

    buf[0] = 0x00;
    ret =  i2c_reg_write_byte(dev_i2c, MAX30102_ADDRESS, MAX30102_INT_ENABLE_2, buf[0]); 
    if(ret) 
      {
      ret1 = 0;
      }

    buf[0] = 0x00;
     ret =  i2c_reg_write_byte(dev_i2c, MAX30102_ADDRESS, MAX30102_FIFO_WRITE_PTR, buf[0]); 
    if(ret)
      {
      ret1 = 0;      
      }

    buf[0] = 0x00;
    ret =  i2c_reg_write_byte(dev_i2c, MAX30102_ADDRESS, MAX30102_OVERFLOW_COUNT, buf[0]);  
    if(ret)
      {
      ret1 = 0;    
      }

    buf[0] = 0x00;
    ret =  i2c_reg_write_byte(dev_i2c, MAX30102_ADDRESS, MAX30102_FIFO_READ_PTR, buf[0]); 
    if(ret)
      {
      ret1 = 0;
      }

    buf[0] = 0x0F; // sample avg = 1, fifo rollover=false, fifo almost full = 17
    ret =  i2c_reg_write_byte(dev_i2c, MAX30102_ADDRESS, MAX30102_FIFO_CONFIG, buf[0]); 
    
    if(ret)
      {
      ret1 = 0;
      }

    buf[0] = 0x03; // 0x02 for Red only, 0x03 for SpO2 mode 0x07 multimode LED
    ret =  i2c_reg_write_byte(dev_i2c, MAX30102_ADDRESS, MAX30102_MODE_CONFIG, buf[0]);
    if(ret)
      {
      ret1 = 0;    
      }

    buf[0] = 0x27; // SPO2_ADC range = 4096nA, SPO2 sample rate (100 Hz), LED pulseWidth (400uS)
    ret =  i2c_reg_write_byte(dev_i2c, MAX30102_ADDRESS, MAX30102_SPO2_CONFIG, buf[0]);
    if(ret)
      {
      ret1 = 0;    
      }

    buf[0] = 0x24; // LED1 current ~ 7mA 
    ret =  i2c_reg_write_byte(dev_i2c, MAX30102_ADDRESS, MAX30102_LED1_PULSE_AMP, buf[0]);  
    if(ret)
      {
      ret1 = 0;
      }

    buf[0] = 0x24; // LED2 current ~ 7mA 
    ret =  i2c_reg_write_byte(dev_i2c, MAX30102_ADDRESS, MAX30102_LED2_PULSE_AMP, buf[0]);  
    if(ret)
      {
      ret1 = 0;   
      }
    return ret1;
}

bool MAX30102_read_reg(const struct device *dev_i2c, uint8_t uch_addr, uint8_t *puch_data)
{
  int ret;
  uint8_t buf[1] = {0x00};

  ret = i2c_burst_read(dev_i2c, MAX30102_ADDRESS, uch_addr, buf, 1);  
  if(ret)
  {  
    printk("MAX30102: Error!\n");
    return false;
  }
  else 
  {
    *puch_data = buf[0];
    return true;
  }
}

bool MAX30102_read_fifo(const struct device *dev_i2c, uint32_t *pun_red_led, uint32_t *pun_ir_led)
{
  int ret;
  uint32_t un_temp;
  unsigned char uch_temp;
  *pun_red_led=0;
  *pun_ir_led=0;
  char ach_i2c_data[6];
  
  //read and clear status register
  //maxim_max30102_read_reg(dev_i2c, MAX30102_INT_STATUS_2, &uch_temp);

  ret = i2c_burst_read(dev_i2c, MAX30102_ADDRESS, MAX30102_REG_FIFO_DATA, ach_i2c_data, 6);
  if(ret) printk("MAX30102: maxim_max30102_read_fifo Error!\n");

  un_temp=(unsigned char) ach_i2c_data[0];
  un_temp<<=16;
  *pun_red_led+=un_temp;
  un_temp=(unsigned char) ach_i2c_data[1];
  un_temp<<=8;
  *pun_red_led+=un_temp;
  un_temp=(unsigned char) ach_i2c_data[2];
  *pun_red_led+=un_temp;
  
  un_temp=(unsigned char) ach_i2c_data[3];
  un_temp<<=16;
  *pun_ir_led+=un_temp;
  un_temp=(unsigned char) ach_i2c_data[4];
  un_temp<<=8;
  *pun_ir_led+=un_temp;
  un_temp=(unsigned char) ach_i2c_data[5];
  *pun_ir_led+=un_temp;
  *pun_red_led&=0x03FFFF;
  *pun_ir_led&=0x03FFFF;

  return true;
}
```

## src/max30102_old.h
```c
#include <zephyr/device.h>
#include <zephyr/drivers/i2c.h>

#include <stdint.h>
#include <stdbool.h>


#ifndef MAX30102_H_
#define MAX30102_H_


#define MAX30102_ADDRESS  0x57 //I2C Address for MAX30102

#define MAX30102_INT_STATUS_1        0x00
#define MAX30102_INT_STATUS_2        0x01
#define MAX30102_INT_ENABLE_1        0x02
#define MAX30102_INT_ENABLE_2        0x03
#define MAX30102_FIFO_WRITE_PTR      0x04
#define MAX30102_OVERFLOW_COUNT      0x05
#define MAX30102_FIFO_READ_PTR       0x06
#define MAX30102_REG_FIFO_DATA       0x07
#define MAX30102_FIFO_CONFIG         0x08
#define MAX30102_MODE_CONFIG         0x09
#define MAX30102_SPO2_CONFIG         0x0A
#define MAX30102_LED1_PULSE_AMP      0x0C
#define MAX30102_LED2_PULSE_AMP      0x0D
#define MAX30102_PARTID              0xFF
#define MAX30102_RESET               0x40


int MAX30102_check(const struct device *dev_i2c);
int MAX30102_reset(const struct device *dev_i2c);
int MAX30102_clear(const struct device *dev_i2c);
int MAX30102_config(const struct device *dev_i2c);
bool MAX30102_read_reg(const struct device *dev_i2c, uint8_t uch_addr, uint8_t *puch_data);
bool MAX30102_read_fifo(const struct device *dev_i2c, uint32_t *pun_red_led, uint32_t *pun_ir_led);

#endif /* MAX30102_H_ */
```
